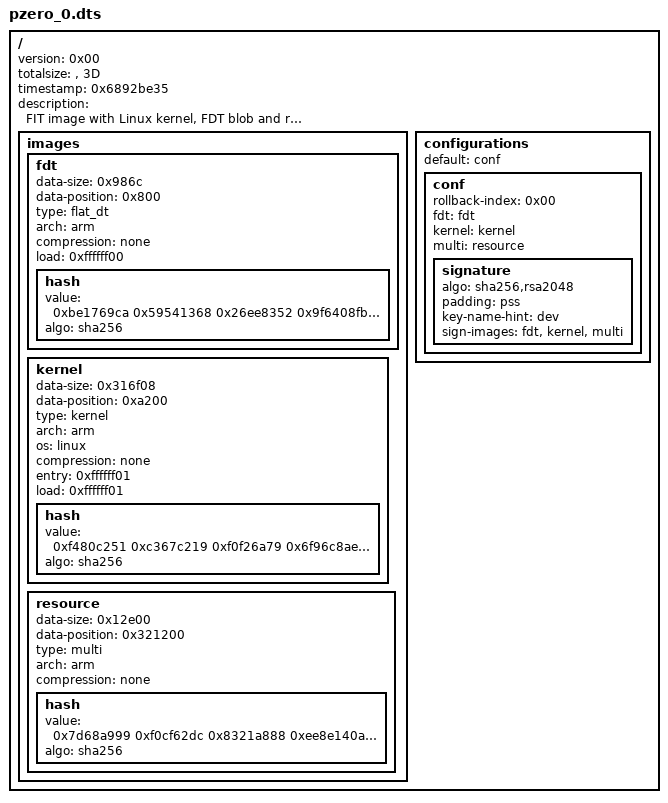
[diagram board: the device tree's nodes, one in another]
/dts-v1/;

/memreserve/	0x000077f2cd000000 0x0000000000000600;
/ {
	version = <0x00>;
	totalsize = "", "3D";
	timestamp = <0x6892be35>;
	description = "FIT image with Linux kernel, FDT blob and resource";

	images {

		fdt {
			data-size = <0x986c>;
			data-position = <0x800>;
			type = "flat_dt";
			arch = "arm";
			compression = "none";
			load = <0xffffff00>;

			hash {
				value = <0xbe1769ca 0x59541368 0x26ee8352 0x9f6408fb 0x9506dbba 0x1b0719db 0xced791ec 0x8c95ab02>;
				algo = "sha256";
			};
		};

		kernel {
			data-size = <0x316f08>;
			data-position = <0xa200>;
			type = "kernel";
			arch = "arm";
			os = "linux";
			compression = "none";
			entry = <0xffffff01>;
			load = <0xffffff01>;

			hash {
				value = <0xf480c251 0xc367c219 0xf0f26a79 0x6f96c8ae 0x3fb65813 0x570cd9a6 0x2ec06767 0xee97b199>;
				algo = "sha256";
			};
		};

		resource {
			data-size = <0x12e00>;
			data-position = <0x321200>;
			type = "multi";
			arch = "arm";
			compression = "none";

			hash {
				value = <0x7d68a999 0xf0cf62dc 0x8321a888 0xee8e140a 0x8699888b 0x8d106a85 0x470f71d4 0x692c6c5b>;
				algo = "sha256";
			};
		};
	};

	configurations {
		default = "conf";

		conf {
			rollback-index = <0x00>;
			fdt = "fdt";
			kernel = "kernel";
			multi = "resource";

			signature {
				algo = "sha256,rsa2048";
				padding = "pss";
				key-name-hint = "dev";
				sign-images = "fdt", "kernel", "multi";
			};
		};
	};
};
